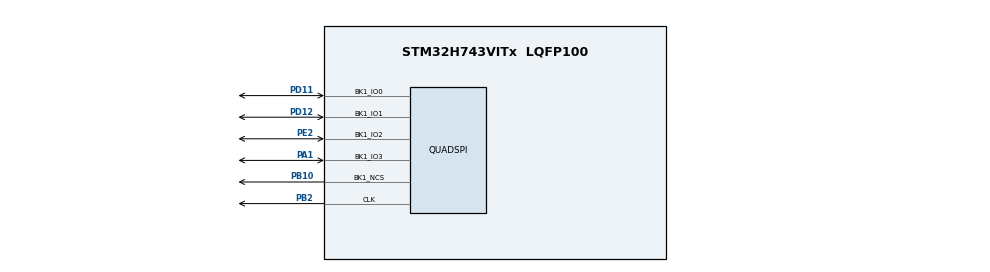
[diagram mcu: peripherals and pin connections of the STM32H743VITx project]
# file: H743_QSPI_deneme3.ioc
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CORTEX_M7.CPU_DCache=Enabled
CORTEX_M7.CPU_ICache=Enabled
Mcu.Family=STM32H7
Mcu.Name=STM32H743VITx
Mcu.Package=LQFP100
NVIC.PriorityGroup=NVIC_PRIORITYGROUP_4
PA1.GPIO_Speed=GPIO_SPEED_FREQ_VERY_HIGH
PA1.Mode=Single Bank 1
PA1.Signal=QUADSPI_BK1_IO3
PA13\ (JTMS/SWDIO).Mode=Serial_Wire
PA13\ (JTMS/SWDIO).Signal=DEBUG_JTMS-SWDIO
PA14\ (JTCK/SWCLK).Mode=Serial_Wire
PA14\ (JTCK/SWCLK).Signal=DEBUG_JTCK-SWCLK
PB10.GPIO_Speed=GPIO_SPEED_FREQ_VERY_HIGH
PB10.Mode=Single Bank 1
PB10.Signal=QUADSPI_BK1_NCS
PB2.GPIO_Speed=GPIO_SPEED_FREQ_VERY_HIGH
PB2.Mode=Single Bank 1
PB2.Signal=QUADSPI_CLK
PD11.GPIO_Speed=GPIO_SPEED_FREQ_VERY_HIGH
PD11.Mode=Single Bank 1
PD11.Signal=QUADSPI_BK1_IO0
PD12.GPIO_Speed=GPIO_SPEED_FREQ_VERY_HIGH
PD12.Mode=Single Bank 1
PD12.Signal=QUADSPI_BK1_IO1
PE2.GPIO_Speed=GPIO_SPEED_FREQ_VERY_HIGH
PE2.Mode=Single Bank 1
PE2.Signal=QUADSPI_BK1_IO2
PH0-OSC_IN\ (PH0).Mode=HSE-External-Oscillator
PH0-OSC_IN\ (PH0).Signal=RCC_OSC_IN
PH1-OSC_OUT\ (PH1).Mode=HSE-External-Oscillator
PH1-OSC_OUT\ (PH1).Signal=RCC_OSC_OUT
ProjectManager.HeapSize=0x200
ProjectManager.StackSize=0x400
ProjectManager.TargetToolchain=STM32CubeIDE
QUADSPI.ChipSelectHighTime=QSPI_CS_HIGH_TIME_5_CYCLE
QUADSPI.ClockPrescaler=1
QUADSPI.FifoThreshold=4
QUADSPI.FlashSize=22
QUADSPI.SampleShifting=QSPI_SAMPLE_SHIFTING_HALFCYCLE
RCC.ADCFreq_Value=16125000
RCC.APB1Freq_Value=66499999.99999999
RCC.APB2Freq_Value=66499999.99999999
RCC.APB3Freq_Value=66499999.99999999
RCC.APB4Freq_Value=66499999.99999999
RCC.CortexFreq_Value=265999999.99999997
RCC.D1PPRE=RCC_APB3_DIV2
RCC.D2PPRE1=RCC_APB1_DIV2
RCC.D2PPRE2=RCC_APB2_DIV2
RCC.D3PPRE=RCC_APB4_DIV2
RCC.DIVM1=6
RCC.DIVN1=399
RCC.HCLKFreq_Value=132999999.99999999
RCC.HPRE=RCC_HCLK_DIV2
RCC.HSE_VALUE=8000000
RCC.PLLFRACN=0
RCC.PLLSourceVirtual=RCC_PLLSOURCE_HSE
RCC.SYSCLKFreq_VALUE=265999999.99999997
RCC.SYSCLKSource=RCC_SYSCLKSOURCE_PLLCLK
RCC.USBFreq_Value=265999999.99999997
board=custom

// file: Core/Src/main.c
/* USER CODE BEGIN Header */
/**
  ******************************************************************************
  * @file           : main.c
  * @brief          : Main program body
  ******************************************************************************
  * @attention
  *
  * <h2><center>&copy; Copyright (c) 2021 STMicroelectronics.
  * All rights reserved.</center></h2>
  *
  * This software component is licensed by ST under BSD 3-Clause license,
  * the "License"; You may not use this file except in compliance with the
  * License. You may obtain a copy of the License at:
  *                        opensource.org/licenses/BSD-3-Clause
  *
  ******************************************************************************
  */
/* USER CODE END Header */
#include "main.h"
#include "quadspi.h"
#include "gpio.h"

/* USER CODE BEGIN Includes */
#include "string.h"
#include "stdio.h"
/* USER CODE END Includes */

void SystemClock_Config(void);

/* USER CODE BEGIN 0 */

u8 writebuf[]={"Hello world from QSPI !"};
u8 readbuf[100];

/* USER CODE END 0 */

int main(void)
{

  /* Enable I-Cache---------------------------------------------------------*/
  SCB_EnableICache();

  /* Enable D-Cache---------------------------------------------------------*/
  SCB_EnableDCache();

  /* MCU Configuration--------------------------------------------------------*/

  /* Reset of all peripherals, Initializes the Flash interface and the Systick. */
  HAL_Init();

  /* Configure the system clock */
  SystemClock_Config();

  /* Initialize all configured peripherals */
  MX_GPIO_Init();
  MX_QUADSPI_Init();
  /* USER CODE BEGIN 2 */
  if (CSP_QUADSPI_Init() != HAL_OK)
  {
	  Error_Handler();
  }

  HAL_Delay(100);

  if (CSP_QSPI_Erase_Chip() != HAL_OK)  //approx 13 second to execute
  {
	  Error_Handler();
  }

  if (CSP_QSPI_WriteMemory(writebuf, 0, sizeof(writebuf)) != HAL_OK)
  {
	  Error_Handler();
  }

  if (CSP_QSPI_Read(readbuf, 0, 100) != HAL_OK)
  {
	  Error_Handler();
  }

  /* USER CODE END 2 */

  /* Infinite loop */
  while (1)
  {

  }
}

void SystemClock_Config(void)
{
  RCC_OscInitTypeDef RCC_OscInitStruct = {0};
  RCC_ClkInitTypeDef RCC_ClkInitStruct = {0};

  /** Supply configuration update enable
  */
  HAL_PWREx_ConfigSupply(PWR_LDO_SUPPLY);
  /** Configure the main internal regulator output voltage
  */
  __HAL_PWR_VOLTAGESCALING_CONFIG(PWR_REGULATOR_VOLTAGE_SCALE2);

  while(!__HAL_PWR_GET_FLAG(PWR_FLAG_VOSRDY)) {}
  /** Initializes the RCC Oscillators according to the specified parameters
  * in the RCC_OscInitTypeDef structure.
  */
  RCC_OscInitStruct.OscillatorType = RCC_OSCILLATORTYPE_HSE;
  RCC_OscInitStruct.HSEState = RCC_HSE_ON;
  RCC_OscInitStruct.PLL.PLLState = RCC_PLL_ON;
  RCC_OscInitStruct.PLL.PLLSource = RCC_PLLSOURCE_HSE;
  RCC_OscInitStruct.PLL.PLLM = 6;
  RCC_OscInitStruct.PLL.PLLN = 399;
  RCC_OscInitStruct.PLL.PLLP = 2;
  RCC_OscInitStruct.PLL.PLLQ = 2;
  RCC_OscInitStruct.PLL.PLLR = 2;
  RCC_OscInitStruct.PLL.PLLRGE = RCC_PLL1VCIRANGE_0;
  RCC_OscInitStruct.PLL.PLLVCOSEL = RCC_PLL1VCOWIDE;
  RCC_OscInitStruct.PLL.PLLFRACN = 0;
  if (HAL_RCC_OscConfig(&RCC_OscInitStruct) != HAL_OK)
  {
    Error_Handler();
  }
  /** Initializes the CPU, AHB and APB buses clocks
  */
  RCC_ClkInitStruct.ClockType = RCC_CLOCKTYPE_HCLK|RCC_CLOCKTYPE_SYSCLK
                              |RCC_CLOCKTYPE_PCLK1|RCC_CLOCKTYPE_PCLK2
                              |RCC_CLOCKTYPE_D3PCLK1|RCC_CLOCKTYPE_D1PCLK1;
  RCC_ClkInitStruct.SYSCLKSource = RCC_SYSCLKSOURCE_PLLCLK;
  RCC_ClkInitStruct.SYSCLKDivider = RCC_SYSCLK_DIV1;
  RCC_ClkInitStruct.AHBCLKDivider = RCC_HCLK_DIV2;
  RCC_ClkInitStruct.APB3CLKDivider = RCC_APB3_DIV2;
  RCC_ClkInitStruct.APB1CLKDivider = RCC_APB1_DIV2;
  RCC_ClkInitStruct.APB2CLKDivider = RCC_APB2_DIV2;
  RCC_ClkInitStruct.APB4CLKDivider = RCC_APB4_DIV2;

  if (HAL_RCC_ClockConfig(&RCC_ClkInitStruct, FLASH_LATENCY_2) != HAL_OK)
  {
    Error_Handler();
  }
}

void Error_Handler(void)
{
  __disable_irq();
  while (1)
  {
  }
}

/************************ (C) COPYRIGHT STMicroelectronics *****END OF FILE****/
